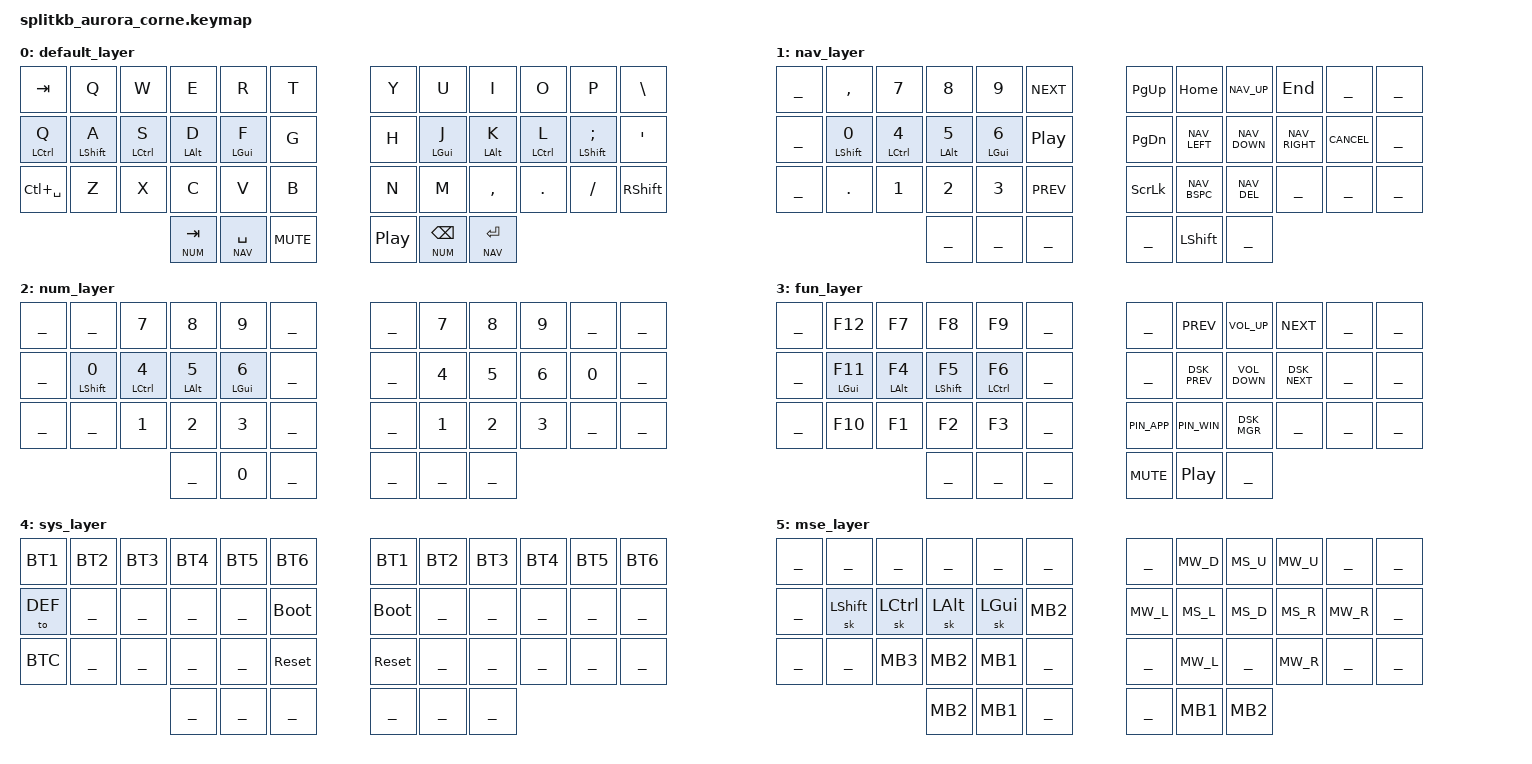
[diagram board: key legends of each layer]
/* source key position labels */
#include "zmk-helpers/key-labels/42.h"

#include "base.keymap"

/ {

  keymap {

    compatible = "zmk,keymap";
                default_layer {
                      bindings = <
//    ┌───────────┬─────────────┬─────────────┬─────────────┬─────────────┬──────┐   ┌──────┬─────────────┬─────────────┬─────────────┬─────────────┬──────┐
//    │    tab    │      Q      │      W      │      E      │      R      │  T   │   │  Y   │      U      │      I      │      O      │      P      │  \   │
//    ├───────────┼─────────────┼─────────────┼─────────────┼─────────────┼──────┤   ├──────┼─────────────┼─────────────┼─────────────┼─────────────┼──────┤
//    │ mt lctl Q │ &hml lsft A │ &hml lctl S │ &hml lalt D │ &hml lgui F │  G   │   │  H   │ &hmr lgui J │ &hmr lalt K │ &hmr lctl L │ &hmr lsft ; │  '   │
//    ├───────────┼─────────────┼─────────────┼─────────────┼─────────────┼──────┤   ├──────┼─────────────┼─────────────┼─────────────┼─────────────┼──────┤
//    │ lctl(spc) │      Z      │      X      │      C      │      V      │  B   │   │  N   │      M      │      ,      │      .      │      /      │ rsft │
//    └───────────┴─────────────┴─────────────┼─────────────┼─────────────┼──────┤   ├──────┼─────────────┼─────────────┼─────────────┴─────────────┴──────┘
//                                            │ lt NUM tab  │ lt NAV spc  │ mute │   │ play │ lt NUM bspc │ lt NAV ent  │
//                                            └─────────────┴─────────────┴──────┘   └──────┴─────────────┴─────────────┘
  &kp TAB         &kp Q          &kp W          &kp E         &kp R           &kp T            &kp Y      &kp U          &kp I         &kp O          &kp P             &kp BSLH
  &mt LCTRL Q     &hml LSHFT A   &hml LCTRL S   &hml LALT D   &hml LGUI F     &kp G            &kp H      &hmr LGUI J    &hmr LALT K   &hmr LCTRL L   &hmr LSHFT SEMI   &kp SQT
  &kp LC(SPACE)   &kp Z          &kp X          &kp C         &kp V           &kp B            &kp N      &kp M          &kp COMMA     &kp DOT        &kp FSLH          &kp RSHFT
                                                &lt NUM TAB   &lt NAV SPACE   &kp C_MUTE       &kp C_PP   &lt NUM BSPC   &lt NAV RETURN
                      >;
                    sensor-bindings = 
                      <&inc_dec_kp C_VOL_UP C_VOL_DN>,
                      <&inc_dec_kp TAB LS(TAB)>;
                };

                nav_layer {
                        bindings = <
//    ┌─────┬─────────────┬─────────────┬─────────────┬─────────────┬──────────┐   ┌──────┬───────────┬───────────┬───────────┬─────────┬─────┐
//    │ ___ │     ___     │     ___     │    prev     │    play     │   next   │   │ pgup │   home    │  _NAV_up  │    end    │   ___   │ ___ │
//    ├─────┼─────────────┼─────────────┼─────────────┼─────────────┼──────────┤   ├──────┼───────────┼───────────┼───────────┼─────────┼─────┤
//    │ ___ │ &hml lsft 0 │ &hml lctl 4 │ &hml lalt 5 │ &hml lgui 6 │ &swapper │   │ pgdn │ _NAV_left │ _NAV_down │ _NAV_rght │ _CANCEL │ ___ │
//    ├─────┼─────────────┼─────────────┼─────────────┼─────────────┼──────────┤   ├──────┼───────────┼───────────┼───────────┼─────────┼─────┤
//    │ ___ │  &sk lsft   │  &sk lctl   │  &sk lalt   │  &sk lgui   │   ___    │   │ slck │ _NAV_bspc │ _NAV_del  │    ___    │   ___   │ ___ │
//    └─────┴─────────────┴─────────────┼─────────────┼─────────────┼──────────┤   ├──────┼───────────┼───────────┼───────────┴─────────┴─────┘
//                                      │     ___     │     ___     │   ___    │   │ ___  │  _CANCEL  │    ___    │
//                                      └─────────────┴─────────────┴──────────┘   └──────┴───────────┴───────────┘
  ___   &kp COMMA   &kp N7             &kp N8     &kp N9       &kp C_NEXT       &kp PG_UP   &kp HOME    _NAV_UP     &kp END      ___       ___
  ___   &hml LSHFT N0   &hml LCTRL N4   &hml LALT N5   &hml LGUI N6   &kp C_PP         &kp PG_DN   _NAV_LEFT   _NAV_DOWN   _NAV_RIGHT   _CANCEL   ___
  ___   &kp DOT       &kp N1       &kp N2       &kp N3       &kp C_PREV              &kp SLCK    _NAV_BSPC   _NAV_DEL    ___          ___       ___
                                        ___            ___            ___              ___         &kp LSHFT     ___
      >;
                    sensor-bindings =
                      <&inc_dec_kp C_VOL_UP C_VOL_DN>,
                      <&inc_dec_kp LG(Z) LG(LS(Z))>;
    };


                num_layer {
                        bindings = <
//    ┌─────┬─────────────┬─────────────┬─────────────┬─────────────┬─────┐   ┌─────┬─────┬─────┬───┬─────┬─────┐
//    │ ___ │     ___     │      7      │      8      │      9      │ ___ │   │ ___ │  7  │  8  │ 9 │ ___ │ ___ │
//    ├─────┼─────────────┼─────────────┼─────────────┼─────────────┼─────┤   ├─────┼─────┼─────┼───┼─────┼─────┤
//    │ ___ │ &hml lsft 0 │ &hml lctl 4 │ &hml lalt 5 │ &hml lgui 6 │ ___ │   │ ___ │  4  │  5  │ 6 │  0  │ ___ │
//    ├─────┼─────────────┼─────────────┼─────────────┼─────────────┼─────┤   ├─────┼─────┼─────┼───┼─────┼─────┤
//    │ ___ │     ___     │      1      │      2      │      3      │ ___ │   │ ___ │  1  │  2  │ 3 │ ___ │ ___ │
//    └─────┴─────────────┴─────────────┼─────────────┼─────────────┼─────┤   ├─────┼─────┼─────┼───┴─────┴─────┘
//                                      │     ___     │      0      │ ___ │   │ ___ │ ___ │ ___ │
//                                      └─────────────┴─────────────┴─────┘   └─────┴─────┴─────┘
  ___   ___             &kp N7          &kp N8         &kp N9         ___       ___   &kp N7   &kp N8   &kp N9   ___      ___
  ___   &hml LSHFT N0   &hml LCTRL N4   &hml LALT N5   &hml LGUI N6   ___       ___   &kp N4   &kp N5   &kp N6   &kp N0   ___
  ___   ___             &kp N1          &kp N2         &kp N3         ___       ___   &kp N1   &kp N2   &kp N3   ___      ___
                                        ___            &kp N0         ___       ___   ___      ___
      >;
                    sensor-bindings =
                      <&inc_dec_kp UP DOWN>,
                      <&inc_dec_kp RIGHT LEFT>;
    };

                fun_layer {
                        bindings = <
//    ┌─────┬───────────────┬──────────────┬──────────────┬──────────────┬─────┐   ┌──────────┬──────────┬───────────┬─────────┬─────┬─────┐
//    │ ___ │      f12      │      f7      │      f8      │      f9      │ ___ │   │   ___    │   prev   │   volu    │  next   │ ___ │ ___ │
//    ├─────┼───────────────┼──────────────┼──────────────┼──────────────┼─────┤   ├──────────┼──────────┼───────────┼─────────┼─────┼─────┤
//    │ ___ │ &hml lgui f11 │ &hml lalt f4 │ &hml lsft f5 │ &hml lctl f6 │ ___ │   │   ___    │ _DSprev  │ _VOL_down │ _DSnext │ ___ │ ___ │
//    ├─────┼───────────────┼──────────────┼──────────────┼──────────────┼─────┤   ├──────────┼──────────┼───────────┼─────────┼─────┼─────┤
//    │ ___ │      f10      │      f1      │      f2      │      f3      │ ___ │   │ _PIN_APP │ _PIN_WIN │ _DSK_MGR  │   ___   │ ___ │ ___ │
//    └─────┴───────────────┴──────────────┼──────────────┼──────────────┼─────┤   ├──────────┼──────────┼───────────┼─────────┴─────┴─────┘
//                                         │     ___      │     ___      │ ___ │   │   mute   │   play   │    ___    │
//                                         └──────────────┴──────────────┴─────┘   └──────────┴──────────┴───────────┘
  ___   &kp F12         &kp F7         &kp F8          &kp F9          ___       ___          &kp C_PREV   &kp C_VOL_UP   &kp C_NEXT   ___   ___
  ___   &hml LGUI F11   &hml LALT F4   &hml LSHFT F5   &hml LCTRL F6   ___       ___          _DSK_PREV    _VOL_DOWN      _DSK_NEXT    ___   ___
  ___   &kp F10         &kp F1         &kp F2          &kp F3          ___       _PIN_APP     _PIN_WIN     _DSK_MGR       ___          ___   ___
                                       ___             ___             ___       &kp C_MUTE   &kp C_PP     ___
      >;
                    sensor-bindings =
                      <&inc_dec_kp C_VOL_UP C_VOL_DN>,
                      <&inc_dec_kp PG_UP PG_DN>;
    };

                sys_layer {
                        bindings = <
//    ┌────────┬──────┬──────┬──────┬──────┬────────────┐   ┌────────────┬──────┬──────┬──────┬──────┬──────┐
//    │  _BT1  │ _BT2 │ _BT3 │ _BT4 │ _BT5 │    _BT6    │   │    _BT1    │ _BT2 │ _BT3 │ _BT4 │ _BT5 │ _BT6 │
//    ├────────┼──────┼──────┼──────┼──────┼────────────┤   ├────────────┼──────┼──────┼──────┼──────┼──────┤
//    │ to DEF │ ___  │ ___  │ ___  │ ___  │    boot    │   │    boot    │ ___  │ ___  │ ___  │ ___  │ ___  │
//    ├────────┼──────┼──────┼──────┼──────┼────────────┤   ├────────────┼──────┼──────┼──────┼──────┼──────┤
//    │  _BTC  │ ___  │ ___  │ ___  │ ___  │ &sys_reset │   │ &sys_reset │ ___  │ ___  │ ___  │ ___  │ ___  │
//    └────────┴──────┴──────┼──────┼──────┼────────────┤   ├────────────┼──────┼──────┼──────┴──────┴──────┘
//                           │ ___  │ ___  │    ___     │   │    ___     │ ___  │ ___  │
//                           └──────┴──────┴────────────┘   └────────────┴──────┴──────┘
  _BT1      _BT2   _BT3   _BT4   _BT5   _BT6              _BT1          _BT2   _BT3   _BT4   _BT5   _BT6
  &to DEF   ___    ___    ___    ___    &bootloader       &bootloader   ___    ___    ___    ___    ___
  _BTC      ___    ___    ___    ___    &sys_reset        &sys_reset    ___    ___    ___    ___    ___
                          ___    ___    ___               ___           ___    ___
      >;
                    sensor-bindings =
                      <&inc_dec_kp C_VOL_UP C_VOL_DN>,
                      <&inc_dec_kp PG_UP PG_DN>;
    };

                mse_layer {
                        bindings = <
//    ┌─────┬──────────┬──────────┬──────────┬──────────┬───────┐   ┌───────┬───────┬───────┬───────┬───────┬─────┐
//    │ ___ │   ___    │   ___    │   ___    │   ___    │  ___  │   │  ___  │ _MW_D │ _MS_U │ _MW_U │  ___  │ ___ │
//    ├─────┼──────────┼──────────┼──────────┼──────────┼───────┤   ├───────┼───────┼───────┼───────┼───────┼─────┤
//    │ ___ │ &sk lsft │ &sk lctl │ &sk lalt │ &sk lgui │ _rclk │   │ _MW_L │ _MS_L │ _MS_D │ _MS_R │ _MW_R │ ___ │
//    ├─────┼──────────┼──────────┼──────────┼──────────┼───────┤   ├───────┼───────┼───────┼───────┼───────┼─────┤
//    │ ___ │   ___    │  _mclk   │  _rclk   │  _lclk   │  ___  │   │  ___  │ _MW_L │  ___  │ _MW_R │  ___  │ ___ │
//    └─────┴──────────┴──────────┼──────────┼──────────┼───────┤   ├───────┼───────┼───────┼───────┴───────┴─────┘
//                                │  _rclk   │  _lclk   │  ___  │   │  ___  │ _lclk │ _rclk │
//                                └──────────┴──────────┴───────┘   └───────┴───────┴───────┘
  ___   ___         ___         ___        ___        ___        ___     _MW_D   _MS_U   _MW_U   ___     ___
  ___   &sk LSHFT   &sk LCTRL   &sk LALT   &sk LGUI   _MB2       _MW_L   _MS_L   _MS_D   _MS_R   _MW_R   ___
  ___   ___         _MB3        _MB2       _MB1       ___        ___     _MW_L   ___     _MW_R   ___     ___
                                _MB2       _MB1       ___        ___     _MB1    _MB2
      >;
                    sensor-bindings =
                      <&inc_dec_kp C_VOL_UP C_VOL_DN>,
                      <&inc_dec_kp PG_UP PG_DN>;
    };
  };
};
